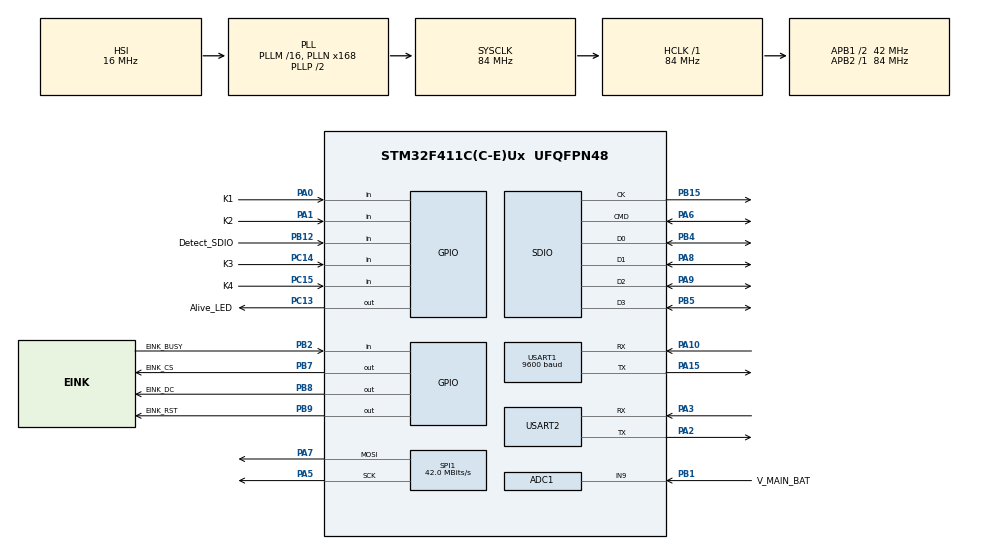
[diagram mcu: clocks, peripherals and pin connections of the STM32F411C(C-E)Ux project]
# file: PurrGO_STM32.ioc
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ADC1.Channel-0\#ChannelRegularConversion=ADC_CHANNEL_9
ADC1.ContinuousConvMode=DISABLE
ADC1.NbrOfConversion=1
ADC1.NbrOfConversionFlag=1
ADC1.Rank-0\#ChannelRegularConversion=1
ADC1.SamplingTime-0\#ChannelRegularConversion=ADC_SAMPLETIME_3CYCLES
ADC1.ScanConvMode=DISABLE
ADC1.master=1
Dma.Request0=USART1_RX
Dma.Request1=SDIO_RX
Dma.Request2=SDIO_TX
Dma.SDIO_RX.1.Direction=DMA_PERIPH_TO_MEMORY
Dma.SDIO_RX.1.FIFOMode=DMA_FIFOMODE_ENABLE
Dma.SDIO_RX.1.FIFOThreshold=DMA_FIFO_THRESHOLD_FULL
Dma.SDIO_RX.1.Instance=DMA2_Stream3
Dma.SDIO_RX.1.MemBurst=DMA_MBURST_INC4
Dma.SDIO_RX.1.MemDataAlignment=DMA_MDATAALIGN_WORD
Dma.SDIO_RX.1.MemInc=DMA_MINC_ENABLE
Dma.SDIO_RX.1.Mode=DMA_PFCTRL
Dma.SDIO_RX.1.PeriphBurst=DMA_PBURST_INC4
Dma.SDIO_RX.1.PeriphDataAlignment=DMA_PDATAALIGN_WORD
Dma.SDIO_RX.1.PeriphInc=DMA_PINC_DISABLE
Dma.SDIO_RX.1.Priority=DMA_PRIORITY_MEDIUM
Dma.SDIO_TX.2.Direction=DMA_MEMORY_TO_PERIPH
Dma.SDIO_TX.2.FIFOMode=DMA_FIFOMODE_ENABLE
Dma.SDIO_TX.2.FIFOThreshold=DMA_FIFO_THRESHOLD_FULL
Dma.SDIO_TX.2.Instance=DMA2_Stream6
Dma.SDIO_TX.2.MemBurst=DMA_MBURST_INC4
Dma.SDIO_TX.2.MemDataAlignment=DMA_MDATAALIGN_WORD
Dma.SDIO_TX.2.MemInc=DMA_MINC_ENABLE
Dma.SDIO_TX.2.Mode=DMA_PFCTRL
Dma.SDIO_TX.2.PeriphBurst=DMA_PBURST_INC4
Dma.SDIO_TX.2.PeriphDataAlignment=DMA_PDATAALIGN_WORD
Dma.SDIO_TX.2.PeriphInc=DMA_PINC_DISABLE
Dma.SDIO_TX.2.Priority=DMA_PRIORITY_MEDIUM
Dma.USART1_RX.0.Direction=DMA_PERIPH_TO_MEMORY
Dma.USART1_RX.0.FIFOMode=DMA_FIFOMODE_DISABLE
Dma.USART1_RX.0.Instance=DMA2_Stream2
Dma.USART1_RX.0.MemDataAlignment=DMA_MDATAALIGN_BYTE
Dma.USART1_RX.0.MemInc=DMA_MINC_ENABLE
Dma.USART1_RX.0.Mode=DMA_CIRCULAR
Dma.USART1_RX.0.PeriphDataAlignment=DMA_PDATAALIGN_BYTE
Dma.USART1_RX.0.PeriphInc=DMA_PINC_DISABLE
Dma.USART1_RX.0.Priority=DMA_PRIORITY_LOW
FATFS.BSP.number=1
FATFS._CODE_PAGE=855
FATFS._FS_LOCK=14
FATFS._USE_LFN=1
FATFS._USE_MKFS=0
FATFS0.BSP.STBoard=false
FATFS0.BSP.api=Unknown
FATFS0.BSP.instance=PB12
FATFS0.BSP.ip=GPIO
FATFS0.BSP.mode=Input
FATFS0.BSP.name=Detect_SDIO
FATFS0.BSP.solution=PB12
Mcu.Family=STM32F4
Mcu.Name=STM32F411C(C-E)Ux
Mcu.Package=UFQFPN48
NVIC.DMA2_Stream2_IRQn=true\:0\:0\:false\:false\:true\:false\:true\:true
NVIC.DMA2_Stream3_IRQn=true\:0\:0\:false\:false\:true\:false\:true\:true
NVIC.DMA2_Stream6_IRQn=true\:0\:0\:false\:false\:true\:false\:true\:true
NVIC.PriorityGroup=NVIC_PRIORITYGROUP_4
NVIC.SDIO_IRQn=true\:0\:0\:false\:false\:true\:true\:true\:true
NVIC.USART1_IRQn=true\:0\:0\:false\:false\:true\:true\:true\:true
PA0-WKUP.GPIO_Label=K1
PA0-WKUP.GPIO_Mode=GPIO_MODE_INPUT
PA0-WKUP.GPIO_PuPd=GPIO_PULLUP
PA0-WKUP.Signal=GPIO_Input
PA1.GPIO_Label=K2
PA1.GPIO_Mode=GPIO_MODE_INPUT
PA1.GPIO_PuPd=GPIO_PULLUP
PA1.Signal=GPIO_Input
PA10.Mode=Asynchronous
PA10.Signal=USART1_RX
PA13.Mode=Serial_Wire
PA13.Signal=SYS_JTMS-SWDIO
PA14.Mode=Serial_Wire
PA14.Signal=SYS_JTCK-SWCLK
PA15.Mode=Asynchronous
PA15.Signal=USART1_TX
PA2.Mode=Asynchronous
PA2.Signal=USART2_TX
PA3.Mode=Asynchronous
PA3.Signal=USART2_RX
PA5.Mode=TX_Only_Simplex_Unidirect_Master
PA5.Signal=SPI1_SCK
PA6.GPIO_PuPd=GPIO_PULLUP
PA6.Mode=SD_4_bits_Wide_bus
PA6.Signal=SDIO_CMD
PA7.Mode=TX_Only_Simplex_Unidirect_Master
PA7.Signal=SPI1_MOSI
PA8.GPIO_PuPd=GPIO_PULLUP
PA8.Mode=SD_4_bits_Wide_bus
PA8.Signal=SDIO_D1
PA9.GPIO_PuPd=GPIO_PULLUP
PA9.Mode=SD_4_bits_Wide_bus
PA9.Signal=SDIO_D2
PB1.GPIO_Label=V_MAIN_BAT
PB1.Signal=ADCx_IN9
PB12.GPIO_Label=Detect_SDIO
PB12.GPIO_PuPd=GPIO_PULLUP
PB12.Signal=GPIO_Input
PB15.Mode=SD_4_bits_Wide_bus
PB15.Signal=SDIO_CK
PB2.GPIO_Label=EINK_BUSY
PB2.Signal=GPIO_Input
PB4.GPIO_PuPd=GPIO_PULLUP
PB4.Mode=SD_4_bits_Wide_bus
PB4.Signal=SDIO_D0
PB5.GPIO_PuPd=GPIO_PULLUP
PB5.Mode=SD_4_bits_Wide_bus
PB5.Signal=SDIO_D3
PB7.GPIO_Label=EINK_CS
PB7.PinState=GPIO_PIN_SET
PB7.Signal=GPIO_Output
PB8.GPIO_Label=EINK_DC
PB8.PinState=GPIO_PIN_RESET
PB8.Signal=GPIO_Output
PB9.GPIO_Label=EINK_RST
PB9.PinState=GPIO_PIN_SET
PB9.Signal=GPIO_Output
PC13-ANTI_TAMP.GPIO_Label=Alive_LED
PC13-ANTI_TAMP.Signal=GPIO_Output
PC14-OSC32_IN.GPIO_Label=K3
PC14-OSC32_IN.GPIO_Mode=GPIO_MODE_INPUT
PC14-OSC32_IN.GPIO_PuPd=GPIO_PULLUP
PC14-OSC32_IN.Signal=GPIO_Input
PC15-OSC32_OUT.GPIO_Label=K4
PC15-OSC32_OUT.GPIO_Mode=GPIO_MODE_INPUT
PC15-OSC32_OUT.GPIO_PuPd=GPIO_PULLUP
PC15-OSC32_OUT.Signal=GPIO_Input
ProjectManager.HeapSize=0x200
ProjectManager.StackSize=0x2000
ProjectManager.TargetToolchain=CMake
RCC.48MHZClocksFreq_Value=42000000
RCC.AHBFreq_Value=84000000
RCC.APB1CLKDivider=RCC_HCLK_DIV2
RCC.APB1Freq_Value=42000000
RCC.APB1TimFreq_Value=84000000
RCC.APB2Freq_Value=84000000
RCC.APB2TimFreq_Value=84000000
RCC.CortexFreq_Value=84000000
RCC.HCLKFreq_Value=84000000
RCC.HSE_VALUE=25000000
RCC.HSI_VALUE=16000000
RCC.LSE_VALUE=32768
RCC.PLLN=168
RCC.SYSCLKFreq_VALUE=84000000
RCC.SYSCLKSource=RCC_SYSCLKSOURCE_PLLCLK
RCC.VCOOutputFreq_Value=168000000
SDIO.HardwareFlowControl=SDIO_HARDWARE_FLOW_CONTROL_ENABLE
SH.ADCx_IN9.0=ADC1_IN9,IN9
SPI1.BaudRatePrescaler=SPI_BAUDRATEPRESCALER_2
SPI1.CalculateBaudRate=42.0 MBits/s
SPI1.Direction=SPI_DIRECTION_2LINES
SPI1.Mode=SPI_MODE_MASTER
SPI1.VirtualType=VM_MASTER
USART1.BaudRate=9600
USART1.VirtualMode=VM_ASYNC
USART2.VirtualMode=VM_ASYNC
VP_FATFS_VS_SDIO.Mode=SDIO
board=custom

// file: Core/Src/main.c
/* USER CODE BEGIN Header */
/**
  ******************************************************************************
  * @file           : main.c
  * @brief          : Main program body
  ******************************************************************************
  * @attention
  *
  * Copyright (c) 2026 STMicroelectronics.
  * All rights reserved.
  *
  * This software is licensed under terms that can be found in the LICENSE file
  * in the root directory of this software component.
  * If no LICENSE file comes with this software, it is provided AS-IS.
  *
  ******************************************************************************
  */
/* USER CODE END Header */
#include "main.h"
#include "adc.h"
#include "dma.h"
#include "fatfs.h"
#include "sdio.h"
#include "spi.h"
#include "usart.h"
#include "gpio.h"

/* USER CODE BEGIN Includes */

#include "stm32_app.h"
#include "purrgo/logger.h"
#include "eink_test.h"

/* USER CODE END Includes */

void SystemClock_Config(void);

int main(void)
{

  /* MCU Configuration--------------------------------------------------------*/

  /* Reset of all peripherals, Initializes the Flash interface and the Systick. */
  HAL_Init();

  /* Configure the system clock */
  SystemClock_Config();

  /* Initialize all configured peripherals */
  MX_GPIO_Init();
  MX_DMA_Init();
  MX_USART2_UART_Init();
  MX_USART1_UART_Init();
  MX_SPI1_Init();
  MX_FATFS_Init();
  MX_SDIO_SD_Init();
  MX_ADC1_Init();
  /* USER CODE BEGIN 2 */

  /* E-Ink hardware test */
  // EinkTest_Run();
  // while (1)  {}

#if defined(PURRGO_EINK_SELFTEST_4GRAY)
  /*
   * Самотест 4-gray через путь приложения (см. eink_test.h).
   * Включается определением PURRGO_EINK_SELFTEST_4GRAY.
   */
  EinkTest_Run4Gray();
  while (1) {}
#endif

#if defined(PURRGO_EINK_SELFTEST_PARTIAL)
  /* Самотест частичного обновления (режим 1-bit). */
  EinkTest_RunPartial();
  while (1) {}
#endif

  purrgo_stm32_init();

  /* USER CODE END 2 */

  /* Infinite loop */
  while (1)
  {

    /* USER CODE BEGIN 3 */

    purrgo_stm32_process();

  }
  /* USER CODE END 3 */
}

void SystemClock_Config(void)
{
  RCC_OscInitTypeDef RCC_OscInitStruct = {0};
  RCC_ClkInitTypeDef RCC_ClkInitStruct = {0};

  /** Configure the main internal regulator output voltage
  */
  __HAL_RCC_PWR_CLK_ENABLE();
  __HAL_PWR_VOLTAGESCALING_CONFIG(PWR_REGULATOR_VOLTAGE_SCALE1);

  /** Initializes the RCC Oscillators according to the specified parameters
  * in the RCC_OscInitTypeDef structure.
  */
  RCC_OscInitStruct.OscillatorType = RCC_OSCILLATORTYPE_HSI;
  RCC_OscInitStruct.HSIState = RCC_HSI_ON;
  RCC_OscInitStruct.HSICalibrationValue = RCC_HSICALIBRATION_DEFAULT;
  RCC_OscInitStruct.PLL.PLLState = RCC_PLL_ON;
  RCC_OscInitStruct.PLL.PLLSource = RCC_PLLSOURCE_HSI;
  RCC_OscInitStruct.PLL.PLLM = 16;
  RCC_OscInitStruct.PLL.PLLN = 168;
  RCC_OscInitStruct.PLL.PLLP = RCC_PLLP_DIV2;
  RCC_OscInitStruct.PLL.PLLQ = 4;
  if (HAL_RCC_OscConfig(&RCC_OscInitStruct) != HAL_OK)
  {
    Error_Handler();
  }

  /** Initializes the CPU, AHB and APB buses clocks
  */
  RCC_ClkInitStruct.ClockType = RCC_CLOCKTYPE_HCLK|RCC_CLOCKTYPE_SYSCLK
                              |RCC_CLOCKTYPE_PCLK1|RCC_CLOCKTYPE_PCLK2;
  RCC_ClkInitStruct.SYSCLKSource = RCC_SYSCLKSOURCE_PLLCLK;
  RCC_ClkInitStruct.AHBCLKDivider = RCC_SYSCLK_DIV1;
  RCC_ClkInitStruct.APB1CLKDivider = RCC_HCLK_DIV2;
  RCC_ClkInitStruct.APB2CLKDivider = RCC_HCLK_DIV1;

  if (HAL_RCC_ClockConfig(&RCC_ClkInitStruct, FLASH_LATENCY_2) != HAL_OK)
  {
    Error_Handler();
  }
}

void Error_Handler(void)
{
  __disable_irq();
  while (1)
  {
  }
}
#ifdef USE_FULL_ASSERT
/**
  * @brief  Reports the name of the source file and the source line number
  *         where the assert_param error has occurred.
  * @param  file: pointer to the source file name
  * @param  line: assert_param error line source number
  * @retval None
  */
void assert_failed(uint8_t *file, uint32_t line)
{
  /* USER CODE BEGIN 6 */
  /* User can add his own implementation to report the file name and line number,
     ex: printf("Wrong parameters value: file %s on line %d\r\n", file, line) */

	PURRGO_LOG("Wrong parameters value: file %s on line %d\r\n", file, line);

  /* USER CODE END 6 */
}
#endif /* USE_FULL_ASSERT */
